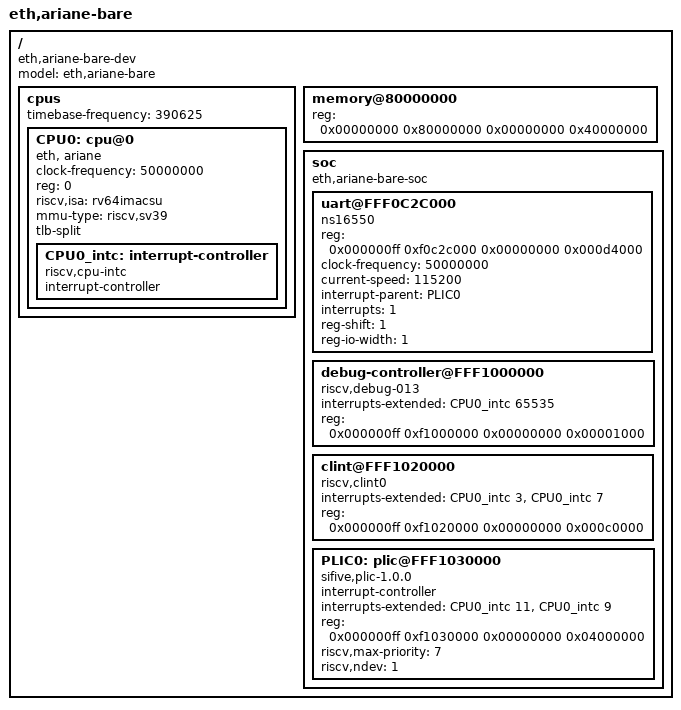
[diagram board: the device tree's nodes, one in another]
// DTS generated with gen_riscv_dts(...) 
// OpenPiton + Ariane framework
// Date: Feb 15 2019 12:30:50

/dts-v1/;

/ {
    #address-cells = <2>;
    #size-cells = <2>;
    compatible = "eth,ariane-bare-dev";
    model = "eth,ariane-bare";
    cpus {
        #address-cells = <1>;
        #size-cells = <0>;
        timebase-frequency = <390625>; 
        
        CPU0: cpu@0 {
            clock-frequency = <50000000>; 
            device_type = "cpu";
            reg = <0>;
            status = "okay";
            compatible = "eth, ariane", "riscv";
            riscv,isa = "rv64imacsu";
            mmu-type = "riscv,sv39";
            tlb-split;
            // HLIC - hart local interrupt controller
            CPU0_intc: interrupt-controller {
                #interrupt-cells = <1>;
                interrupt-controller;
                compatible = "riscv,cpu-intc";
            };
        };
        
    };
    
    memory@80000000 {
        device_type = "memory";
        reg = < 0x00000000 0x80000000 0x00000000 0x40000000 >;
    };
                    
    soc {
        #address-cells = <2>;
        #size-cells = <2>;
        compatible = "eth,ariane-bare-soc", "simple-bus";
        ranges;
    
        uart@FFF0C2C000 {
            compatible = "ns16550";
            reg = < 0x000000ff 0xf0c2c000 0x00000000 0x000d4000 >;
            clock-frequency = <50000000>;
            current-speed = <115200>;
            interrupt-parent = <&PLIC0>;
            interrupts = <1>;
            reg-shift = <1>; // regs are spaced on 8 bit boundary
            reg-io-width = <1>; // only 8-bit access are supported
        };
            
        debug-controller@FFF1000000 {
            compatible = "riscv,debug-013";
            interrupts-extended = <&CPU0_intc 65535 >;
            reg = < 0x000000ff 0xf1000000 0x00000000 0x00001000 >;
            reg-names = "control";
        };
            
        clint@FFF1020000 {
            compatible = "riscv,clint0";
            interrupts-extended = <&CPU0_intc 3 &CPU0_intc 7 >;
            reg = < 0x000000ff 0xf1020000 0x00000000 0x000c0000 >;
            reg-names = "control";
        };
            
        PLIC0: plic@FFF1030000 {
            #address-cells = <0>;
            #interrupt-cells = <1>;
            compatible = "sifive,plic-1.0.0", "riscv,plic0";
            interrupt-controller;
            interrupts-extended = <&CPU0_intc 11 &CPU0_intc 9 >;
            reg = < 0x000000ff 0xf1030000 0x00000000 0x04000000 >;
            reg-names = "control";
            riscv,max-priority = <7>;
            riscv,ndev = <1>;
        };
                
    };
};
    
